# PIC32MZ2048EFM144 register map
Registers are 32-bit, access not given, reset 0x0 unless marked. A register's access mark holds for its fields unless they carry their own. Offsets are from the block's base; [hi:lo] are bit positions; 'fields as' and 'values as' point back to an identical list.

## ICAP7 — ICAP7 peripheral
Base 0xBF842C00
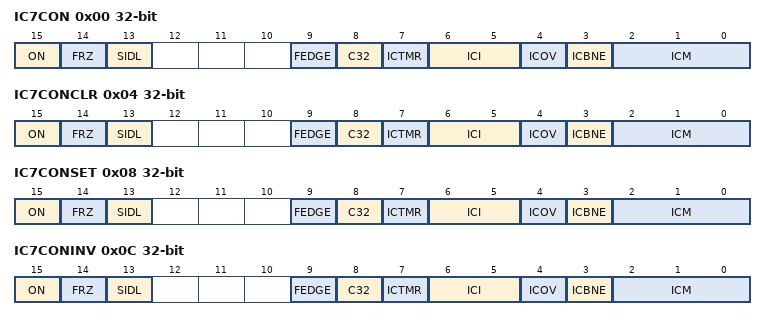
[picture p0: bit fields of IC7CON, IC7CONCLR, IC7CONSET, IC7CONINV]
0x00 IC7CON
  [15] ON, [14] FRZ, [13] SIDL, [9] FEDGE, [8] C32, [7] ICTMR, [6:5] ICI, [4] ICOV, [3] ICBNE, [2:0] ICM
0x04 IC7CONCLR
  fields as IC7CON
0x08 IC7CONSET
  fields as IC7CON
0x0C IC7CONINV
  fields as IC7CON
0x10 IC7BUF

## ICAP8 — ICAP8 peripheral
Base 0xBF842E00
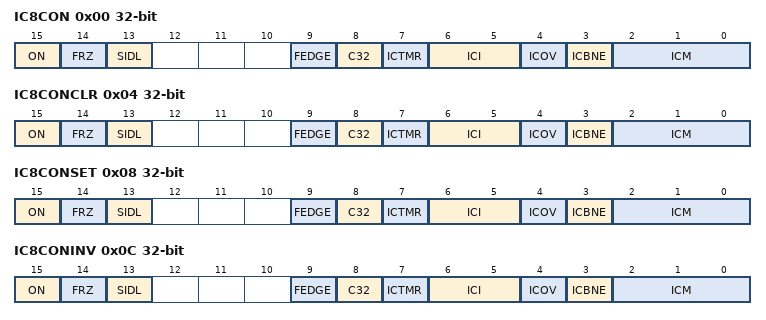
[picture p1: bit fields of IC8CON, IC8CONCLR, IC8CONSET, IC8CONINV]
0x00 IC8CON
  [15] ON, [14] FRZ, [13] SIDL, [9] FEDGE, [8] C32, [7] ICTMR, [6:5] ICI, [4] ICOV, [3] ICBNE, [2:0] ICM
0x04 IC8CONCLR
  fields as IC8CON
0x08 IC8CONSET
  fields as IC8CON
0x0C IC8CONINV
  fields as IC8CON
0x10 IC8BUF

## ICAP9 — ICAP9 peripheral
Base 0xBF843000
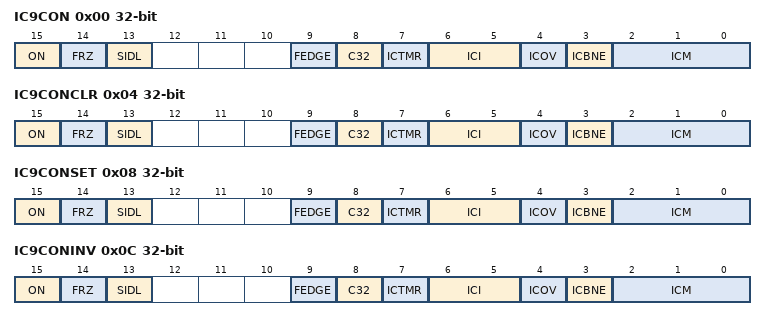
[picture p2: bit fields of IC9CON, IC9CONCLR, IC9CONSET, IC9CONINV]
0x00 IC9CON
  [15] ON, [14] FRZ, [13] SIDL, [9] FEDGE, [8] C32, [7] ICTMR, [6:5] ICI, [4] ICOV, [3] ICBNE, [2:0] ICM
0x04 IC9CONCLR
  fields as IC9CON
0x08 IC9CONSET
  fields as IC9CON
0x0C IC9CONINV
  fields as IC9CON
0x10 IC9BUF

## OCMP1 — OCMP1 peripheral
Base 0xBF844000
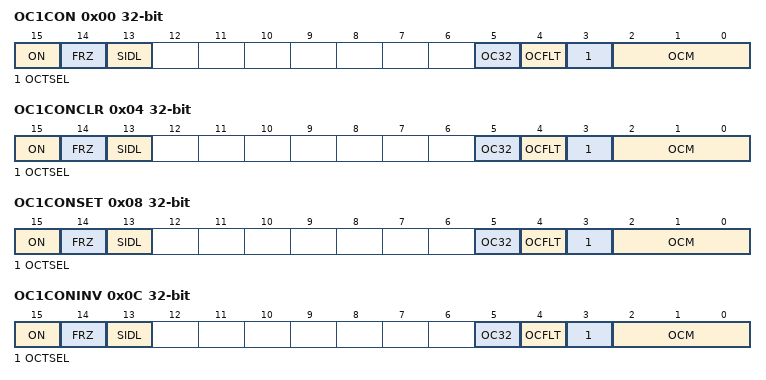
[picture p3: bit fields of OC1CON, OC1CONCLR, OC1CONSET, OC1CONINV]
0x00 OC1CON
  [15] ON, [14] FRZ, [13] SIDL, [5] OC32, [4] OCFLT, [3] OCTSEL, [2:0] OCM
0x04 OC1CONCLR
  fields as OC1CON
0x08 OC1CONSET
  fields as OC1CON
0x0C OC1CONINV
  fields as OC1CON
0x10 OC1R
0x14 OC1RCLR
  [31:0] OC1R
0x18 OC1RSET
  [31:0] OC1R
0x1C OC1RINV
  [31:0] OC1R
0x20 OC1RS
0x24 OC1RSCLR
  [31:0] OC1RS
0x28 OC1RSSET
  [31:0] OC1RS
0x2C OC1RSINV
  [31:0] OC1RS

## OCMP2 — OCMP2 peripheral
Base 0xBF844200
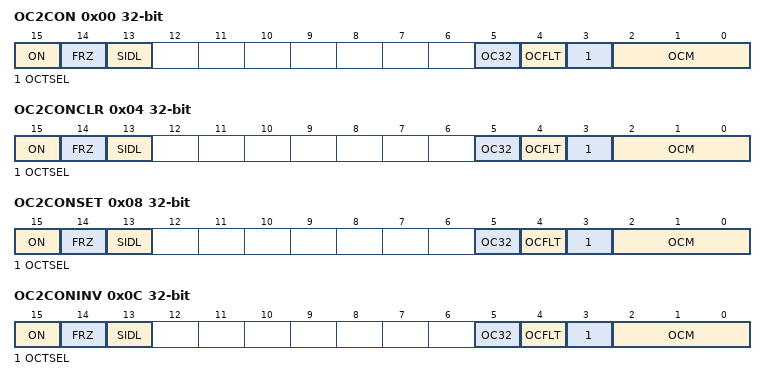
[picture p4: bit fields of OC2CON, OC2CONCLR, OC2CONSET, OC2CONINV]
0x00 OC2CON
  [15] ON, [14] FRZ, [13] SIDL, [5] OC32, [4] OCFLT, [3] OCTSEL, [2:0] OCM
0x04 OC2CONCLR
  fields as OC2CON
0x08 OC2CONSET
  fields as OC2CON
0x0C OC2CONINV
  fields as OC2CON
0x10 OC2R
0x14 OC2RCLR
  [31:0] OC2R
0x18 OC2RSET
  [31:0] OC2R
0x1C OC2RINV
  [31:0] OC2R
0x20 OC2RS
0x24 OC2RSCLR
  [31:0] OC2RS
0x28 OC2RSSET
  [31:0] OC2RS
0x2C OC2RSINV
  [31:0] OC2RS

## OCMP3 — OCMP3 peripheral
Base 0xBF844400
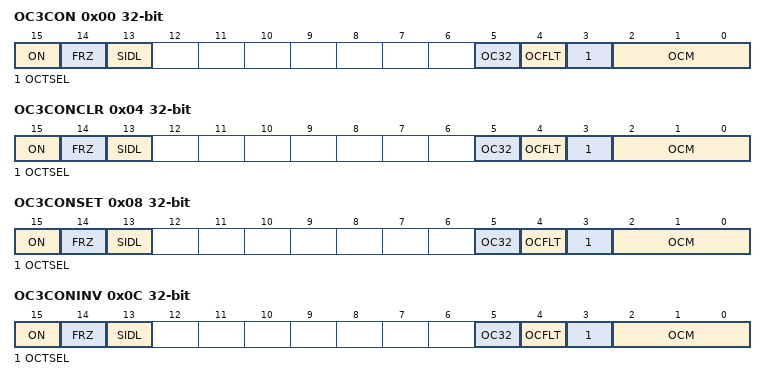
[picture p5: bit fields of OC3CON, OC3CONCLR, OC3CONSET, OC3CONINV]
0x00 OC3CON
  [15] ON, [14] FRZ, [13] SIDL, [5] OC32, [4] OCFLT, [3] OCTSEL, [2:0] OCM
0x04 OC3CONCLR
  fields as OC3CON
0x08 OC3CONSET
  fields as OC3CON
0x0C OC3CONINV
  fields as OC3CON
0x10 OC3R
0x14 OC3RCLR
  [31:0] OC3R
0x18 OC3RSET
  [31:0] OC3R
0x1C OC3RINV
  [31:0] OC3R
0x20 OC3RS
0x24 OC3RSCLR
  [31:0] OC3RS
0x28 OC3RSSET
  [31:0] OC3RS
0x2C OC3RSINV
  [31:0] OC3RS

## OCMP4 — OCMP4 peripheral
Base 0xBF844600
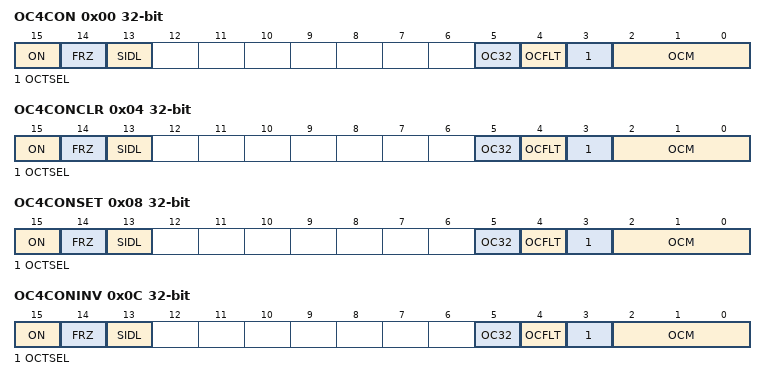
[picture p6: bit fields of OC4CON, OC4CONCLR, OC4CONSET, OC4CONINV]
0x00 OC4CON
  [15] ON, [14] FRZ, [13] SIDL, [5] OC32, [4] OCFLT, [3] OCTSEL, [2:0] OCM
0x04 OC4CONCLR
  fields as OC4CON
0x08 OC4CONSET
  fields as OC4CON
0x0C OC4CONINV
  fields as OC4CON
0x10 OC4R
0x14 OC4RCLR
  [31:0] OC4R
0x18 OC4RSET
  [31:0] OC4R
0x1C OC4RINV
  [31:0] OC4R
0x20 OC4RS
0x24 OC4RSCLR
  [31:0] OC4RS
0x28 OC4RSSET
  [31:0] OC4RS
0x2C OC4RSINV
  [31:0] OC4RS

## OCMP5 — OCMP5 peripheral
Base 0xBF844800
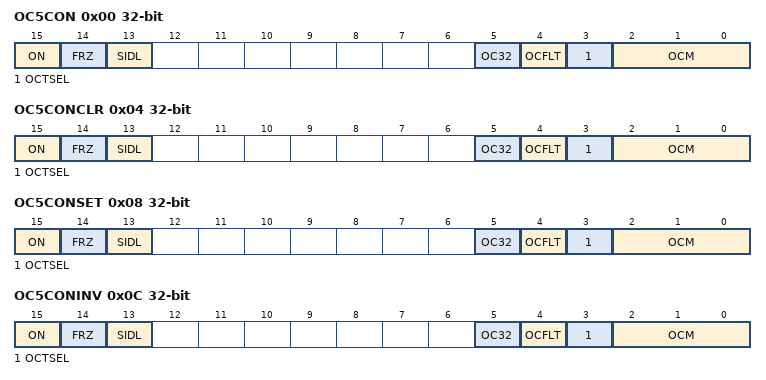
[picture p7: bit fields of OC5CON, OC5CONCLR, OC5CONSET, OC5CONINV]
0x00 OC5CON
  [15] ON, [14] FRZ, [13] SIDL, [5] OC32, [4] OCFLT, [3] OCTSEL, [2:0] OCM
0x04 OC5CONCLR
  fields as OC5CON
0x08 OC5CONSET
  fields as OC5CON
0x0C OC5CONINV
  fields as OC5CON
0x10 OC5R
0x14 OC5RCLR
  [31:0] OC5R
0x18 OC5RSET
  [31:0] OC5R
0x1C OC5RINV
  [31:0] OC5R
0x20 OC5RS
0x24 OC5RSCLR
  [31:0] OC5RS
0x28 OC5RSSET
  [31:0] OC5RS
0x2C OC5RSINV
  [31:0] OC5RS

## OCMP6 — OCMP6 peripheral
Base 0xBF844A00
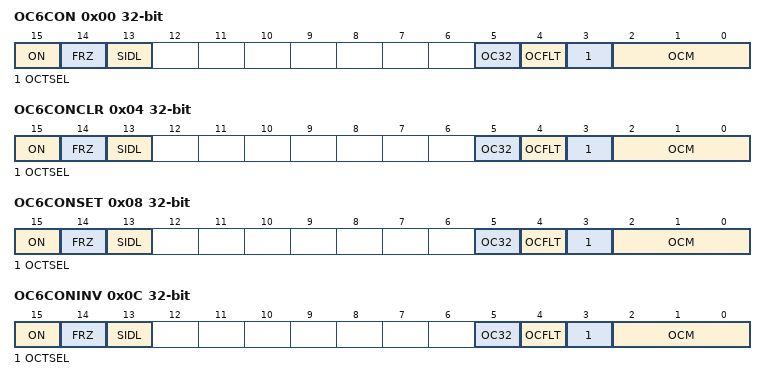
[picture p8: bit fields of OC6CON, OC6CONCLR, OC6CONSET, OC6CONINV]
0x00 OC6CON
  [15] ON, [14] FRZ, [13] SIDL, [5] OC32, [4] OCFLT, [3] OCTSEL, [2:0] OCM
0x04 OC6CONCLR
  fields as OC6CON
0x08 OC6CONSET
  fields as OC6CON
0x0C OC6CONINV
  fields as OC6CON
0x10 OC6R
0x14 OC6RCLR
  [31:0] OC6R
0x18 OC6RSET
  [31:0] OC6R
0x1C OC6RINV
  [31:0] OC6R
0x20 OC6RS
0x24 OC6RSCLR
  [31:0] OC6RS
0x28 OC6RSSET
  [31:0] OC6RS
0x2C OC6RSINV
  [31:0] OC6RS

## OCMP7 — OCMP7 peripheral
Base 0xBF844C00
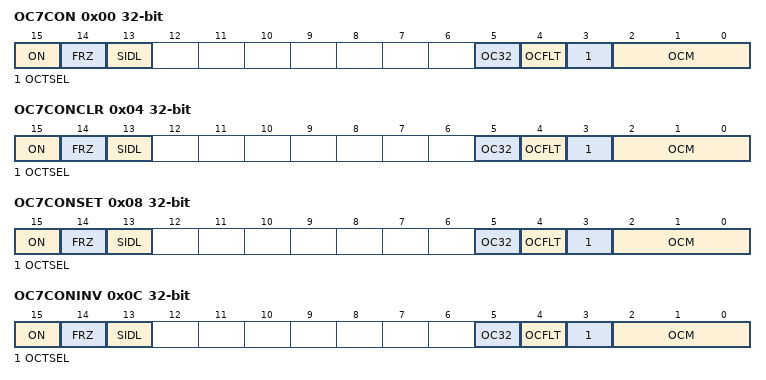
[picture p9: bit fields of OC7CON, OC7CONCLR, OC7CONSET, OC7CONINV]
0x00 OC7CON
  [15] ON, [14] FRZ, [13] SIDL, [5] OC32, [4] OCFLT, [3] OCTSEL, [2:0] OCM
0x04 OC7CONCLR
  fields as OC7CON
0x08 OC7CONSET
  fields as OC7CON
0x0C OC7CONINV
  fields as OC7CON
0x10 OC7R
0x14 OC7RCLR
  [31:0] OC7R
0x18 OC7RSET
  [31:0] OC7R
0x1C OC7RINV
  [31:0] OC7R
0x20 OC7RS
0x24 OC7RSCLR
  [31:0] OC7RS
0x28 OC7RSSET
  [31:0] OC7RS
0x2C OC7RSINV
  [31:0] OC7RS
